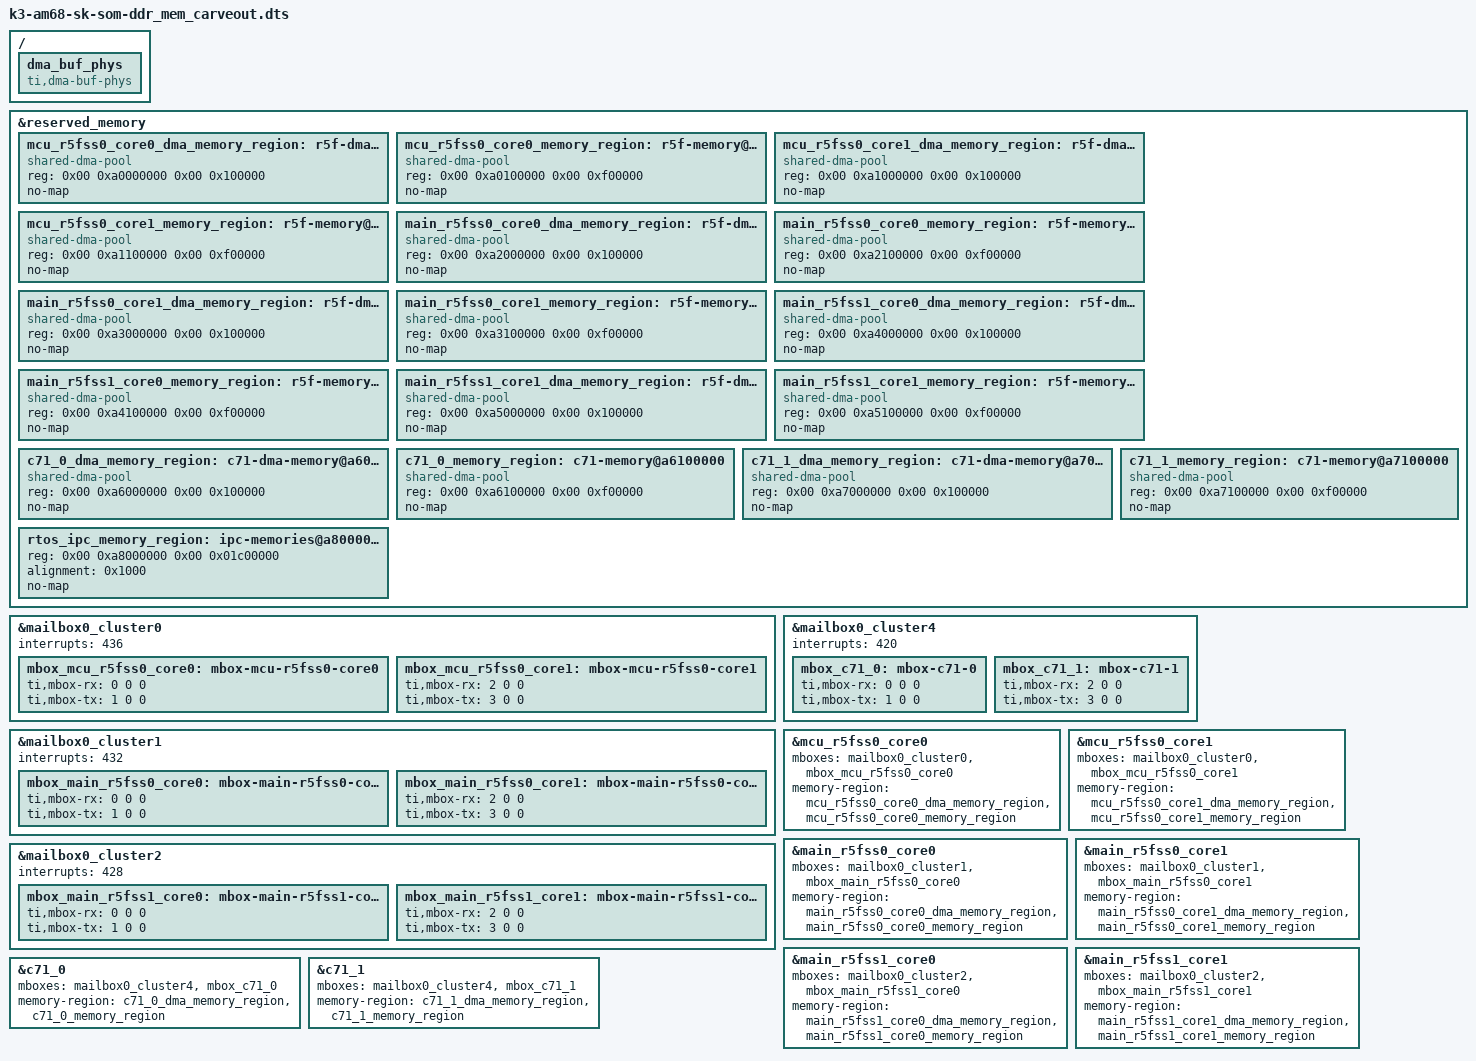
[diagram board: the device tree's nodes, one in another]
// SPDX-License-Identifier: GPL-2.0
/**
 * DT Overlay for DDR careveout memory nodes for R5F and C71x DSPs.
 *
 * Copyright (C) 2022 Texas Instruments Incorporated - https://www.ti.com/
 */

/dts-v1/;
/plugin/;

#include <dt-bindings/gpio/gpio.h>
#include <dt-bindings/interrupt-controller/irq.h>
#include <dt-bindings/pinctrl/k3.h>

/ {
	fragment@101 {
		target-path = "/";

		__overlay__ {
			dma_buf_phys {
				compatible = "ti,dma-buf-phys";
			};
		};
	};
};

&reserved_memory {
	#address-cells = <2>;
	#size-cells = <2>;

	mcu_r5fss0_core0_dma_memory_region: r5f-dma-memory@a0000000 {
		compatible = "shared-dma-pool";
		reg = <0x00 0xa0000000 0x00 0x100000>;
		no-map;
	};

	mcu_r5fss0_core0_memory_region: r5f-memory@a0100000 {
		compatible = "shared-dma-pool";
		reg = <0x00 0xa0100000 0x00 0xf00000>;
		no-map;
	};

	mcu_r5fss0_core1_dma_memory_region: r5f-dma-memory@a1000000 {
		compatible = "shared-dma-pool";
		reg = <0x00 0xa1000000 0x00 0x100000>;
		no-map;
	};

	mcu_r5fss0_core1_memory_region: r5f-memory@a1100000 {
		compatible = "shared-dma-pool";
		reg = <0x00 0xa1100000 0x00 0xf00000>;
		no-map;
	};

	main_r5fss0_core0_dma_memory_region: r5f-dma-memory@a2000000 {
		compatible = "shared-dma-pool";
		reg = <0x00 0xa2000000 0x00 0x100000>;
		no-map;
	};

	main_r5fss0_core0_memory_region: r5f-memory@a2100000 {
		compatible = "shared-dma-pool";
		reg = <0x00 0xa2100000 0x00 0xf00000>;
		no-map;
	};

	main_r5fss0_core1_dma_memory_region: r5f-dma-memory@a3000000 {
		compatible = "shared-dma-pool";
		reg = <0x00 0xa3000000 0x00 0x100000>;
		no-map;
	};

	main_r5fss0_core1_memory_region: r5f-memory@a3100000 {
		compatible = "shared-dma-pool";
		reg = <0x00 0xa3100000 0x00 0xf00000>;
		no-map;
	};

	main_r5fss1_core0_dma_memory_region: r5f-dma-memory@a4000000 {
		compatible = "shared-dma-pool";
		reg = <0x00 0xa4000000 0x00 0x100000>;
		no-map;
	};

	main_r5fss1_core0_memory_region: r5f-memory@a4100000 {
		compatible = "shared-dma-pool";
		reg = <0x00 0xa4100000 0x00 0xf00000>;
		no-map;
	};

	main_r5fss1_core1_dma_memory_region: r5f-dma-memory@a5000000 {
		compatible = "shared-dma-pool";
		reg = <0x00 0xa5000000 0x00 0x100000>;
		no-map;
	};

	main_r5fss1_core1_memory_region: r5f-memory@a5100000 {
		compatible = "shared-dma-pool";
		reg = <0x00 0xa5100000 0x00 0xf00000>;
		no-map;
	};

	c71_0_dma_memory_region: c71-dma-memory@a6000000 {
		compatible = "shared-dma-pool";
		reg = <0x00 0xa6000000 0x00 0x100000>;
		no-map;
	};

	c71_0_memory_region: c71-memory@a6100000 {
		compatible = "shared-dma-pool";
		reg = <0x00 0xa6100000 0x00 0xf00000>;
		no-map;
	};

	c71_1_dma_memory_region: c71-dma-memory@a7000000 {
		compatible = "shared-dma-pool";
		reg = <0x00 0xa7000000 0x00 0x100000>;
		no-map;
	};

	c71_1_memory_region: c71-memory@a7100000 {
		compatible = "shared-dma-pool";
		reg = <0x00 0xa7100000 0x00 0xf00000>;
		no-map;
	};

	rtos_ipc_memory_region: ipc-memories@a8000000 {
		reg = <0x00 0xa8000000 0x00 0x01c00000>;
		alignment = <0x1000>;
		no-map;
	};
};

&mailbox0_cluster0 {
	status = "okay";
	interrupts = <436>;

	mbox_mcu_r5fss0_core0: mbox-mcu-r5fss0-core0 {
		ti,mbox-rx = <0 0 0>;
		ti,mbox-tx = <1 0 0>;
	};

	mbox_mcu_r5fss0_core1: mbox-mcu-r5fss0-core1 {
		ti,mbox-rx = <2 0 0>;
		ti,mbox-tx = <3 0 0>;
	};
};

&mailbox0_cluster1 {
	status = "okay";
	interrupts = <432>;

	mbox_main_r5fss0_core0: mbox-main-r5fss0-core0 {
		ti,mbox-rx = <0 0 0>;
		ti,mbox-tx = <1 0 0>;
	};

	mbox_main_r5fss0_core1: mbox-main-r5fss0-core1 {
		ti,mbox-rx = <2 0 0>;
		ti,mbox-tx = <3 0 0>;
	};
};

&mailbox0_cluster2 {
	status = "okay";
	interrupts = <428>;

	mbox_main_r5fss1_core0: mbox-main-r5fss1-core0 {
		ti,mbox-rx = <0 0 0>;
		ti,mbox-tx = <1 0 0>;
	};

	mbox_main_r5fss1_core1: mbox-main-r5fss1-core1 {
		ti,mbox-rx = <2 0 0>;
		ti,mbox-tx = <3 0 0>;
	};
};

&mailbox0_cluster4 {
	status = "okay";
	interrupts = <420>;

	mbox_c71_0: mbox-c71-0 {
		ti,mbox-rx = <0 0 0>;
		ti,mbox-tx = <1 0 0>;
	};

	mbox_c71_1: mbox-c71-1 {
		ti,mbox-rx = <2 0 0>;
		ti,mbox-tx = <3 0 0>;
	};
};

&mcu_r5fss0_core0 {
	status = "okay";
	mboxes = <&mailbox0_cluster0 &mbox_mcu_r5fss0_core0>;
	memory-region = <&mcu_r5fss0_core0_dma_memory_region>,
			<&mcu_r5fss0_core0_memory_region>;
};

&mcu_r5fss0_core1 {
	status = "okay";
	mboxes = <&mailbox0_cluster0 &mbox_mcu_r5fss0_core1>;
	memory-region = <&mcu_r5fss0_core1_dma_memory_region>,
			<&mcu_r5fss0_core1_memory_region>;
};

&main_r5fss0_core0 {
	status = "okay";
	mboxes = <&mailbox0_cluster1 &mbox_main_r5fss0_core0>;
	memory-region = <&main_r5fss0_core0_dma_memory_region>,
			<&main_r5fss0_core0_memory_region>;
};

&main_r5fss0_core1 {
	status = "okay";
	mboxes = <&mailbox0_cluster1 &mbox_main_r5fss0_core1>;
	memory-region = <&main_r5fss0_core1_dma_memory_region>,
			<&main_r5fss0_core1_memory_region>;
};

&main_r5fss1_core0 {
	status = "okay";
	mboxes = <&mailbox0_cluster2 &mbox_main_r5fss1_core0>;
	memory-region = <&main_r5fss1_core0_dma_memory_region>,
			<&main_r5fss1_core0_memory_region>;
};

&main_r5fss1_core1 {
	status = "okay";
	mboxes = <&mailbox0_cluster2 &mbox_main_r5fss1_core1>;
	memory-region = <&main_r5fss1_core1_dma_memory_region>,
			<&main_r5fss1_core1_memory_region>;
};

&c71_0 {
	status = "okay";
	mboxes = <&mailbox0_cluster4 &mbox_c71_0>;
	memory-region = <&c71_0_dma_memory_region>,
			<&c71_0_memory_region>;
};

&c71_1 {
	status = "okay";
	mboxes = <&mailbox0_cluster4 &mbox_c71_1>;
	memory-region = <&c71_1_dma_memory_region>,
			<&c71_1_memory_region>;
};
